# PIC16F1619 register map
Vendor: Microchip
Registers are 8-bit, read-write, reset 0x0 unless marked. A register's access mark holds for its fields unless they carry their own. Addresses are absolute, and some are shared; only a register's first bit layout is shown; [hi:lo] are bit positions; {n}, {i} and the like mark numbered series.

## SFR
0x00 INDF0 reset not defined — (power-on value xxxxxxxx)
0x01 INDF1 reset not defined — (power-on value xxxxxxxx)
0x02 PCL
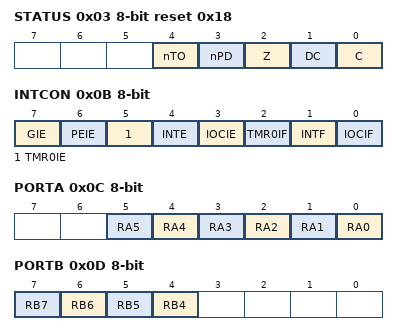
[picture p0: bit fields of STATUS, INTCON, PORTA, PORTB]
0x03 STATUS reset 0x18
  [4] nTO ro, [3] nPD ro, [2] Z, [1] DC, [0] C
0x04 FSR0L
0x05 FSR0H
0x06 FSR1L
0x07 FSR1H
0x08 BSR
  [4:0] BSR
0x09 WREG
  [7:0] WREG0
0x0A PCLATH
  [6:0] PCLATH
0x0B INTCON
  [7] GIE, [6] PEIE, [5] TMR0IE, [4] INTE, [3] IOCIE, [2] TMR0IF, [1] INTF, [0] IOCIF ro
0x0C PORTA reset not defined — (power-on value --xxxxxx)
  [n] RA{n} (n=0..5)
0x0D PORTB reset not defined — (power-on value xxxx----)
  [n] RB{n} (n=4..7)
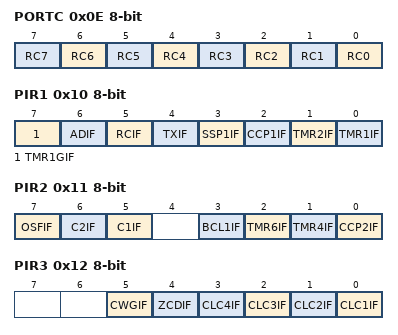
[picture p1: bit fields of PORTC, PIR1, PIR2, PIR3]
0x0E PORTC reset not defined — (power-on value xxxxxxxx)
  [n] RC{n} (n=0..7)
0x10 PIR1
  [7] TMR1GIF — Timer1 Gate Interrupt Flag bit
  [6] ADIF — A/D Converter Interrupt Flag bit
  [5] RCIF
  [4] TXIF
  [3] SSP1IF
  [2] CCP1IF
  [1] TMR2IF — TMR2 to PR2 Match Interrupt Flag bit
  [0] TMR1IF — TMR1 Overflow Interrupt Flag bit
0x11 PIR2
  [7] OSFIF
  [6] C2IF — Numerically Controlled Oscillator Flag bit
  [5] C1IF — Numerically Controlled Oscillator Flag bit
  [3] BCL1IF
  [2] TMR6IF — Numerically Controlled Oscillator Flag bit
  [1] TMR4IF
  [0] CCP2IF
0x12 PIR3
  [5] CWGIF, [4] ZCDIF, [n-1] CLC{n}IF (n=1..4)
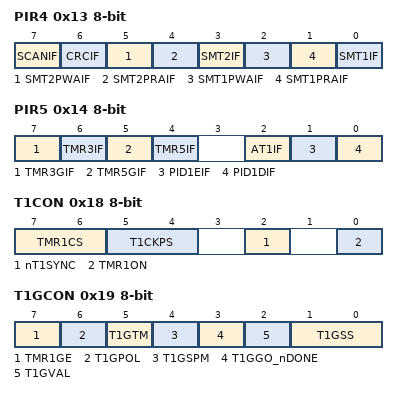
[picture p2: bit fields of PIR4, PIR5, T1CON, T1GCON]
0x13 PIR4
  [7] SCANIF, [6] CRCIF, [5] SMT2PWAIF, [4] SMT2PRAIF, [3] SMT2IF, [2] SMT1PWAIF, [1] SMT1PRAIF, [0] SMT1IF
0x14 PIR5
  [7] TMR3GIF, [6] TMR3IF, [5] TMR5GIF, [4] TMR5IF, [2] AT1IF ro, [1] PID1EIF, [0] PID1DIF
0x15 TMR0 reset not defined — (power-on value xxxxxxxx)
0x16 TMR1L reset not defined — (power-on value xxxxxxxx)
0x17 TMR1H reset not defined — (power-on value xxxxxxxx)
0x18 T1CON
  [7:6] TMR1CS, [5:4] T1CKPS, [2] nT1SYNC, [0] TMR1ON
0x19 T1GCON reset not defined — (power-on value 00000x00)
  [7] TMR1GE, [6] T1GPOL, [5] T1GTM, [4] T1GSPM, [3] T1GGO_nDONE, [2] T1GVAL ro, [1:0] T1GSS
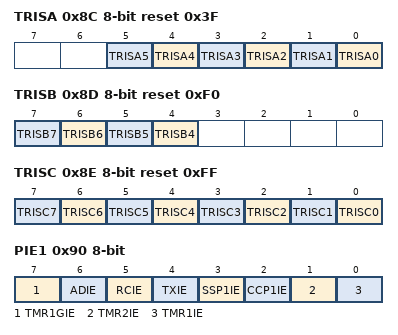
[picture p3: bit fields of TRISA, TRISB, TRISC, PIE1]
0x8C TRISA reset 0x3F — PORTA Data Direction Control Register
  [n] TRISA{n} (n=0..5)
0x8D TRISB reset 0xF0
  [n] TRISB{n} (n=4..7)
0x8E TRISC reset 0xFF — PORTC Data Direction Control Register
  [n] TRISC{n} (n=0..7)
0x90 PIE1 — Peripheral Interrupt Enable Register 1
  [7] TMR1GIE — Timer1 Gate Interrupt Enable bit
  [6] ADIE — A/D Converter Interrupt Enable bit
  [5] RCIE
  [4] TXIE
  [3] SSP1IE
  [2] CCP1IE
  [1] TMR2IE — TMR2 to PR2 Match Interrupt Enable bit
  [0] TMR1IE — TMR1 Overflow Interrupt Enable bit
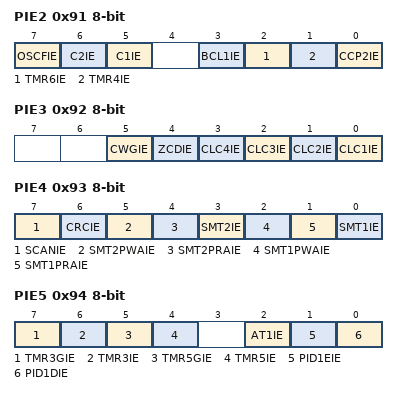
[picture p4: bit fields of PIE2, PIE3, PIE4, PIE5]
0x91 PIE2 — Peripheral Interrupt Enable Register 2
  [7] OSCFIE, [6] C2IE, [5] C1IE, [3] BCL1IE, [2] TMR6IE, [1] TMR4IE, [0] CCP2IE
0x92 PIE3 — Peripheral Interrupt Enable Register 3
  [5] CWGIE, [4] ZCDIE, [n-1] CLC{n}IE (n=1..4)
0x93 PIE4
  [7] SCANIE, [6] CRCIE, [5] SMT2PWAIE, [4] SMT2PRAIE, [3] SMT2IE, [2] SMT1PWAIE, [1] SMT1PRAIE, [0] SMT1IE
0x94 PIE5 reset not defined — (power-on value xxxx-xxx)
  [7] TMR3GIE, [6] TMR3IE, [5] TMR5GIE, [4] TMR5IE, [2] AT1IE, [1] PID1EIE, [0] PID1DIE
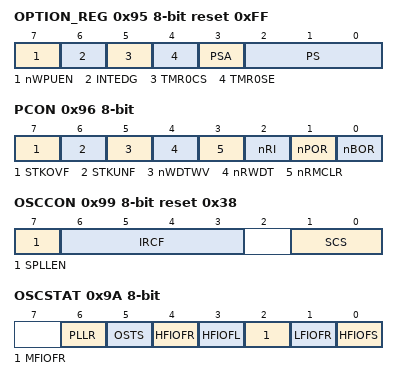
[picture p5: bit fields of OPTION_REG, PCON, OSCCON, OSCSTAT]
0x95 OPTION_REG reset 0xFF — Option Register
  [7] nWPUEN — Weak Pull-up Enable bit
  [6] INTEDG — Interrupt Edge Select bit
  [5] TMR0CS
  [4] TMR0SE — TMR0 Source Edge Select bit
  [3] PSA — Prescaler Active bit
  [2:0] PS
0x96 PCON reset not defined — Power Control Register (power-on value 001111qq)
  [7] STKOVF — Stack Overflow Flag bit
  [6] STKUNF — Stack Underflow Flag bit
  [5] nWDTWV
  [4] nRWDT
  [3] nRMCLR — MCLR Reset Flag bit
  [2] nRI — RESET Instruction Flag bit
  [1] nPOR — Power-on Reset Status bit
  [0] nBOR — Brown-out Reset Status bit
0x98 OSCTUNE
  [5:0] TUN
0x99 OSCCON reset 0x38 — Oscillator Control Register
  [7] SPLLEN, [6:3] IRCF, [1:0] SCS
0x9A OSCSTAT ro reset not defined — Oscillator Status Register (power-on value -0q00q00)
  [6] PLLR
  [5] OSTS
  [4] HFIOFR
  [3] HFIOFL
  [2] MFIOFR
  [1] LFIOFR — Low Freqency Internal Oscillator Ready bit
  [0] HFIOFS — Low Freqency Internal Oscillator Ready bit
0x9B ADRESL reset not defined — A/D Result Register LSB (power-on value xxxxxxxx)
0x9C ADRESH reset not defined — A/D Result Register MSB (power-on value xxxxxxxx)
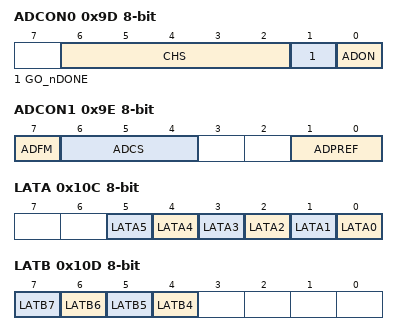
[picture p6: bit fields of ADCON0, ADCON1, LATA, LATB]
0x9D ADCON0 — Analog-to-Digital Control Register 0
  [6:2] CHS
  [1] GO_nDONE — A/D Conversion Status bit
  [0] ADON — A/D Module Enable bit
0x9E ADCON1 — Analog-to-Digital Control Register 1
  [7] ADFM — A/D Result Format Select bit
  [6:4] ADCS
  [1:0] ADPREF
0x9F ADCON2 — Analog-to-Digital Control Register 2
  [7:3] TRIGSEL
0x10C LATA reset not defined — (power-on value --xxxxxx)
  [n] LATA{n} (n=0..5)
0x10D LATB reset not defined — (power-on value xxxx----)
  [n] LATB{n} (n=4..7)
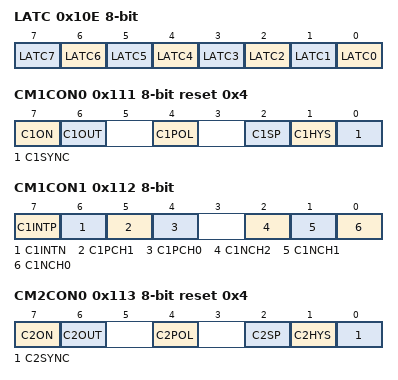
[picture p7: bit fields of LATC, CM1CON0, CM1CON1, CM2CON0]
0x10E LATC reset not defined — (power-on value xxxxxxxx)
  [n] LATC{n} (n=0..7)
0x111 CM1CON0 reset 0x4
  [7] C1ON — Comparator Enable bit
  [6] C1OUT ro — Comparator Output bit
  [4] C1POL — Comparator Output Polarity Select bit
  [2] C1SP — Comparator Speed/Power Select bit
  [1] C1HYS — Comparator Hysteresis Enable bit
  [0] C1SYNC — Comparator Output Synchronous Mode bit
0x112 CM1CON1
  [7] C1INTP — Comparator Interrupt on Positive going edge Enable bits
  [6] C1INTN — Comparator Interrupt on Negative going edge Enable bits
  [5] C1PCH1 — Comparator Positive Input Channel Select bits
  [4] C1PCH0 — Comparator Positive Input Channel Select bits
  [2] C1NCH2
  [1] C1NCH1 — Comparator Negative Input Channel Select bits
  [0] C1NCH0 — Comparator Negative Input Channel Select bits
0x113 CM2CON0 reset 0x4
  [7] C2ON, [6] C2OUT ro, [4] C2POL, [2] C2SP, [1] C2HYS, [0] C2SYNC
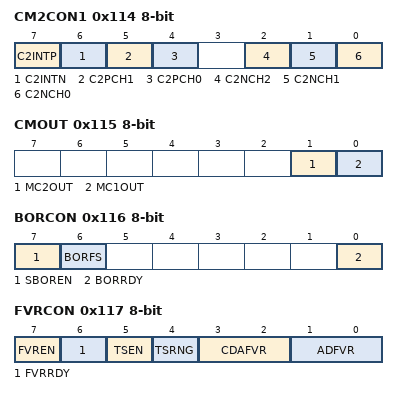
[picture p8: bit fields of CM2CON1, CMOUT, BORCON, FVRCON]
0x114 CM2CON1
  [7] C2INTP — Comparator Interrupt on Positive going edge Enable bits
  [6] C2INTN — Comparator Interrupt on Negative going edge Enable bits
  [5] C2PCH1 — Comparator Positive Input Channel Select bits
  [4] C2PCH0 — Comparator Positive Input Channel Select bits
  [2] C2NCH2
  [1] C2NCH1 — Comparator Negative Input Channel Select bits
  [0] C2NCH0 — Comparator Negative Input Channel Select bits
0x115 CMOUT ro — Comparator Output Register
  [1] MC2OUT, [0] MC1OUT
0x116 BORCON reset not defined — Brown-out Reset Control Register (power-on value 10-----q)
  [7] SBOREN — Software Brown Out Reset Enable bit
  [6] BORFS
  [0] BORRDY ro — Brown-out Reset Circuit Ready Status bit
0x117 FVRCON reset not defined — Voltage Reference Control Register 0 (power-on value 0q00xx00)
  [7] FVREN — Fixed Voltage Reference Enable
  [6] FVRRDY ro — Fixed Voltage Reference Ready Flag
  [5] TSEN — Temperature Sensor Enable
  [4] TSRNG — Temperature Sensor Range Select
  [3:2] CDAFVR
  [1:0] ADFVR — A/D Converter Fixed Voltage Reference Selection
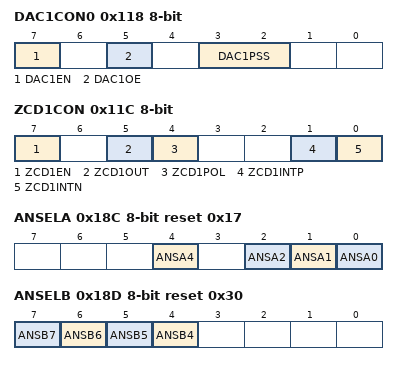
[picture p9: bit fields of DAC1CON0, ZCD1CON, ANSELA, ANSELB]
0x118 DAC1CON0 — Voltage Reference Control Register 0
  [7] DAC1EN — DAC 1 Enable bit
  [5] DAC1OE
  [3:2] DAC1PSS
0x119 DAC1CON1 — Voltage Reference Control Register 1
  [7:0] DAC1R
0x11C ZCD1CON reset not defined — (power-on value 0-x0--00)
  [7] ZCD1EN, [5] ZCD1OUT ro, [4] ZCD1POL, [1] ZCD1INTP, [0] ZCD1INTN
0x18C ANSELA reset 0x17
  [4] ANSA4, [2] ANSA2, [1] ANSA1, [0] ANSA0
0x18D ANSELB reset 0x30
  [n] ANSB{n} (n=4..7)
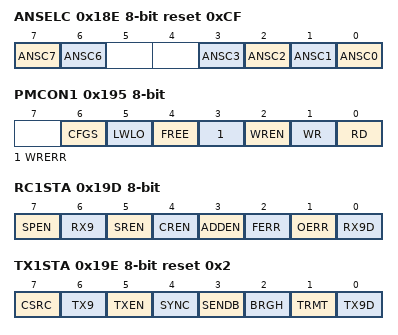
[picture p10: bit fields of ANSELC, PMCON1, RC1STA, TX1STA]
0x18E ANSELC reset 0xCF
  [7] ANSC7, [6] ANSC6, [n] ANSC{n} (n=0..3)
0x191 PMADRL
0x192 PMADRH reset 0x80
  [6:0] PMADRH
0x193 PMDATL reset not defined — (power-on value xxxxxxxx)
0x194 PMDATH reset not defined — (power-on value --xxxxxx)
  [5:0] PMDATH
0x195 PMCON1 reset not defined — (power-on value -000x000)
  [6] CFGS — FLASH Program / Data EEPROM or Configuration Select bit
  [5] LWLO — Load Write Latches Only bit
  [4] FREE — Program FLASH Erase Enable bit
  [3] WRERR — Sequence Error Flag bit
  [2] WREN — Program/Erase Enable bit
  [1] WR — Write Control bit (can only be set)
  [0] RD — Read Control bit (can only be set)
0x196 PMCON2 wo
0x197 VREGCON reset 0x1
  [1:0] VREGPM
0x199 RC1REG ro
0x19A TX1REG
0x19B SP1BRGL
0x19C SP1BRGH
0x19D RC1STA
  [7] SPEN, [6] RX9, [5] SREN, [4] CREN, [3] ADDEN, [2] FERR ro, [1] OERR ro, [0] RX9D ro
0x19E TX1STA reset 0x2
  [7] CSRC, [6] TX9, [5] TXEN, [4] SYNC, [3] SENDB, [2] BRGH, [1] TRMT ro, [0] TX9D
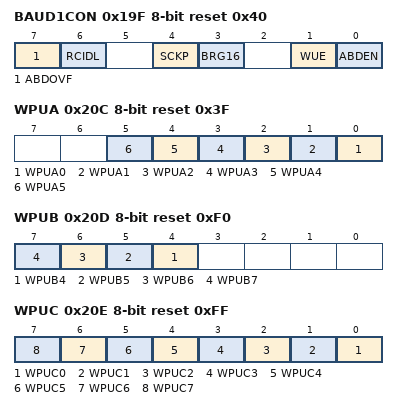
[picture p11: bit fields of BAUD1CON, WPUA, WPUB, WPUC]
0x19F BAUD1CON reset 0x40
  [7] ABDOVF ro, [6] RCIDL ro, [4] SCKP, [3] BRG16, [1] WUE, [0] ABDEN
0x20C WPUA reset 0x3F
  [n] WPUA{n} (n=0..5)
0x20D WPUB reset 0xF0
  [n] WPUB{n} (n=4..7)
0x20E WPUC reset 0xFF
  [n] WPUC{n} (n=0..7)
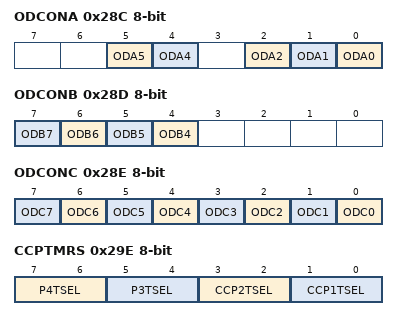
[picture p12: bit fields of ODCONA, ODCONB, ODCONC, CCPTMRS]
0x28C ODCONA
  [5] ODA5, [4] ODA4, [2] ODA2, [1] ODA1, [0] ODA0
0x28D ODCONB
  [n] ODB{n} (n=4..7)
0x28E ODCONC
  [n] ODC{n} (n=0..7)
0x29E CCPTMRS
  [7:6] P4TSEL, [5:4] P3TSEL, [3:2] CCP2TSEL, [1:0] CCP1TSEL
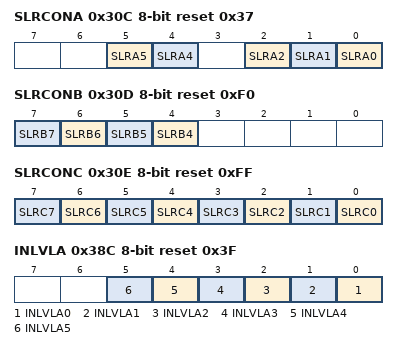
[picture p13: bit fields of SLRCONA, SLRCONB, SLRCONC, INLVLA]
0x30C SLRCONA reset 0x37
  [5] SLRA5, [4] SLRA4, [2] SLRA2, [1] SLRA1, [0] SLRA0
0x30D SLRCONB reset 0xF0
  [n] SLRB{n} (n=4..7)
0x30E SLRCONC reset 0xFF
  [n] SLRC{n} (n=0..7)
0x38C INLVLA reset 0x3F
  [n] INLVLA{n} (n=0..5)
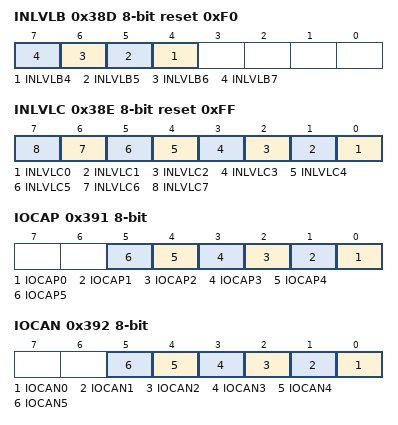
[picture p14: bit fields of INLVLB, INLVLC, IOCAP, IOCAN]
0x38D INLVLB reset 0xF0
  [n] INLVLB{n} (n=4..7)
0x38E INLVLC reset 0xFF
  [n] INLVLC{n} (n=0..7)
0x391 IOCAP
  [n] IOCAP{n} (n=0..5)
0x392 IOCAN
  [n] IOCAN{n} (n=0..5)
0x393 IOCAF
  [n] IOCAF{n} (n=0..5)
0x394 IOCBP
  [n] IOCBP{n} (n=4..7)
0x395 IOCBN
  [n] IOCBN{n} (n=4..7)
0x396 IOCBF
  [n] IOCBF{n} (n=4..7)
0x397 IOCCP
  [n] IOCCP{n} (n=0..7)
0x398 IOCCN
  [n] IOCCN{n} (n=0..7)
0x399 IOCCF
  [n] IOCCF{n} (n=0..7)
0x40E HIDRVC
  [5] HIDC5, [4] HIDC4
0x493 TMR3L reset not defined — (power-on value xxxxxxxx)
0x494 TMR3H reset not defined — (power-on value xxxxxxxx)
0x495 T3CON reset not defined — (power-on value xxxx-x-x)
  [7:6] TMR3CS, [5:4] T3CKPS, [2] T3SYNC, [0] TMR3ON
0x496 T3GCON reset not defined — (power-on value xxxxxxxx)
  [7] TMR3GE, [6] T3GPOL, [5] T3GTM, [4] T3GSPM, [3] T3GGO_nDONE, [2] T3GVAL, [1:0] T3GSS
0x49A TMR5L reset not defined — (power-on value xxxxxxxx)
0x49B TMR5H reset not defined — (power-on value xxxxxxxx)
0x49C T5CON reset not defined — (power-on value xxxx-x-x)
  [7:6] TMR5CS, [5:4] T5CKPS, [2] T5SYNC, [0] TMR5ON
0x49D T5GCON reset not defined — (power-on value xxxxxxxx)
  [7] TMR5GE, [6] T5GPOL, [5] T5GTM, [4] T5GSPM, [3] T5GGO_nDONE, [2] T5GVAL, [1:0] T5GSS
0x816 AT1IR0
  [2] AT1PHSIF, [1] AT1MISSIF, [0] AT1PERIF
0x817 AT1IE0
  [2] AT1PHSIE, [1] AT1MISSIE, [0] AT1PERIE
0x818 AT1IR1
  [2] AT1CC3IF, [1] AT1CC2IF, [0] AT1CC1IF
0x819 AT1IE1
  [2] AT1CC3IE, [1] AT1CC2IE, [0] AT1CC1IE
0xE0F PPSLOCK
  [0] PPSLOCKED
0xE10 INTPPS reset 0x2
  [4:0] INTPPS
0xE11 T0CKIPPS reset 0x2
  [4:0] T0CKIPPS
0xE12 T1CKIPPS reset 0x5
  [4:0] T1CKIPPS
0xE13 T1GPPS reset 0x4
  [4:0] T1GPPS
0xE14 CCP1PPS reset 0x15
  [4:0] CCP1PPS
0xE15 CCP2PPS reset 0x13
  [4:0] CCP2PPS
0xE16 ATINPPS reset 0x15
  [4:0] ATINPPS
0xE17 CWG1INPPS reset 0x2
  [4:0] CWG1INPPS
0xE18 T2CKIPPS reset 0x5
  [4:0] T2CKIPPS
0xE19 T3CKIPPS reset 0x15
  [4:0] T3CKIPPS
0xE1A T3GPPS reset 0x14
  [4:0] T3GPPS
0xE1B T4CKIPPS reset 0x11
  [4:0] T4CKIPPS
0xE1C T5CKIPPS reset 0x10
  [4:0] T5CKIPPS
0xE1D T5GPPS reset 0x13
  [4:0] T5GPPS
0xE1E T6CKIPPS reset 0x3
  [4:0] T6CKIPPS
0xE1F ATCC1PPS reset 0x13
  [4:0] ATCC1PPS
0xE20 SSPCLKPPS reset 0xE
  [4:0] SSPCLKPPS
0xE21 SSPDATPPS reset 0xC
  [4:0] SSPDATPPS
0xE22 SSPSSPPS reset 0x13
  [4:0] SSPSSPPS
0xE23 ATCC2PPS reset 0x14
  [4:0] ATCC2PPS
0xE24 RXPPS reset 0xD
  [4:0] RXPPS
0xE25 CKPPS reset 0xF
  [4:0] CKPPS
0xE26 SMT1SIGPPS reset 0x4
  [4:0] SMT1SIGPPS
0xE27 SMT1WINPPS reset 0x5
  [4:0] SMT1WINPPS
0xE28 CLCIN0PPS reset 0x13
  [4:0] CLCN0PPS
0xE29 CLCIN1PPS reset 0x14
  [4:0] CLCIN1PPS
0xE2A CLCIN2PPS reset 0x11
  [4:0] CLCIN2PPS
0xE2B CLCIN3PPS reset 0x5
  [4:0] CLCIN3PPS
0xE2C SMT2SIGPPS reset 0x11
  [4:0] SMT2SIGPPS
0xE2D SMT2WINPPS reset 0x3
  [4:0] SMT2WINPPS
0xE2E ATCC3PPS reset 0x15
  [4:0] ATCC3PPS
{0xE90+i} RA{i}PPS (i=0..2)
  [n] RA{i}PPS{n} (n=0..4)
0xE94 RA4PPS
  [n] RA4PPS{n} (n=0..4)
0xE95 RA5PPS
  [n] RA5PPS{n} (n=0..4)
{0xE98+i} RB{i}PPS (i=4..7)
  [n] RB{i}PPS{n} (n=0..4)
{0xEA0+i} RC{i}PPS (i=0..7)
  [n] RC{i}PPS{n} (n=0..4)
0xF0F CLCDATA
  [n-1] MLC{n}OUT (n=1..4)
0xFE4 STATUS_SHAD reset not defined — (power-on value -----xxx)
  [2] Z_SHAD, [1] DC_SHAD, [0] C_SHAD
0xFE5 WREG_SHAD reset not defined — (power-on value xxxxxxxx)
0xFE6 BSR_SHAD reset not defined — (power-on value ---xxxxx)
  [4:0] BSR_SHAD
0xFE7 PCLATH_SHAD reset not defined — (power-on value -xxxxxxx)
  [6:0] PCLATH_SHAD
0xFE8 FSR0L_SHAD reset not defined — (power-on value xxxxxxxx)
0xFE9 FSR0H_SHAD reset not defined — (power-on value xxxxxxxx)
0xFEA FSR1L_SHAD reset not defined — (power-on value xxxxxxxx)
0xFEB FSR1H_SHAD reset not defined — (power-on value xxxxxxxx)
0xFED STKPTR reset 0x1F
  [4:0] STKPTR
0xFEE TOSL reset not defined — (power-on value xxxxxxxx)
0xFEF TOSH reset not defined — (power-on value -xxxxxxx)
  [6:0] TOSH
